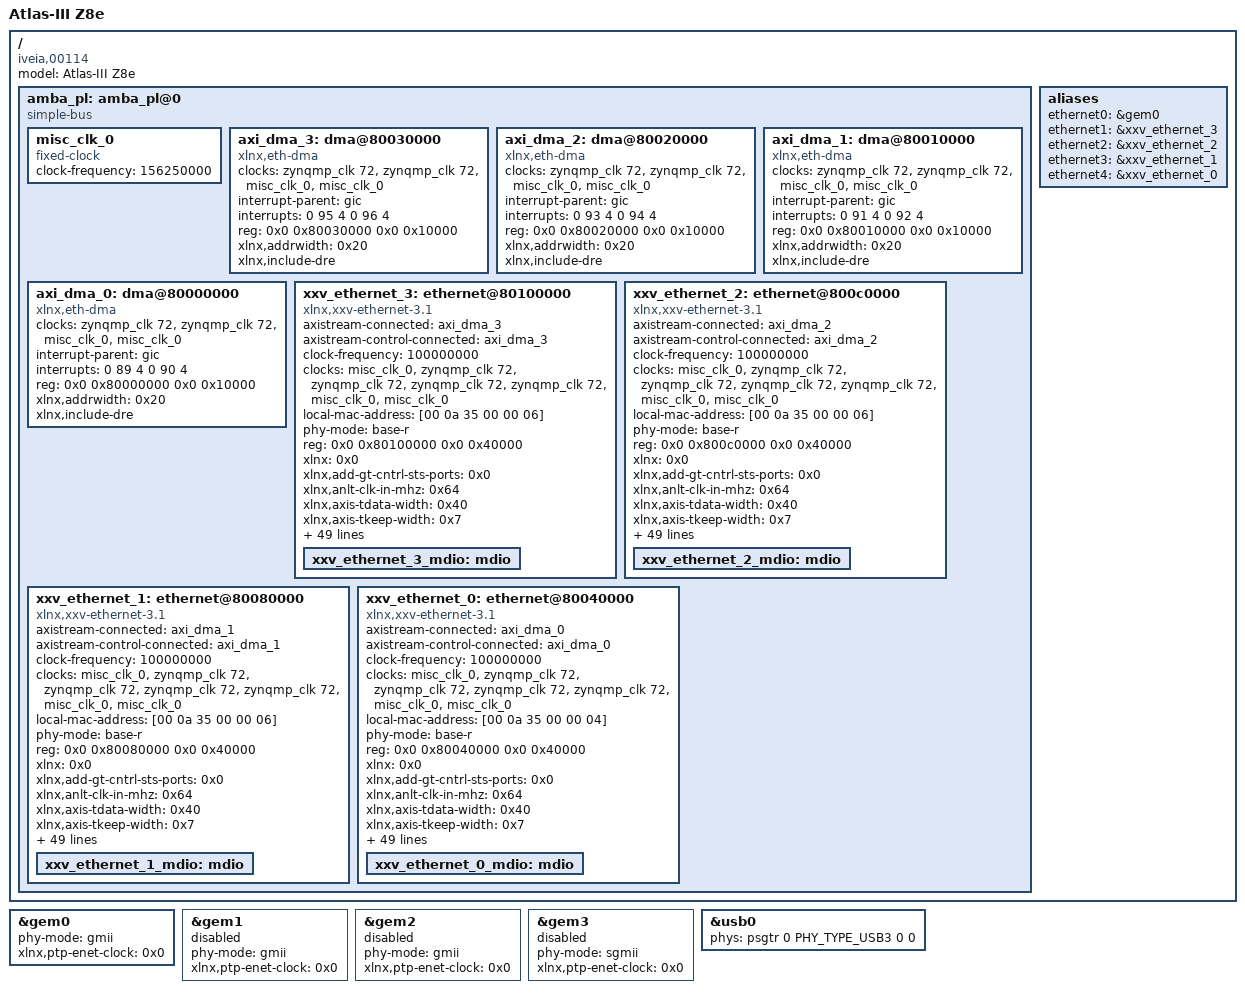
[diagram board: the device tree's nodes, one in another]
#include <atlas-z8-inc.dtsi>

/ {
  amba_pl: amba_pl@0 {
    #address-cells = <2>;
    #size-cells = <2>;
    compatible = "simple-bus";
    ranges ;
    misc_clk_0: misc_clk_0 {
      #clock-cells = <0>;
      clock-frequency = <156250000>;
      compatible = "fixed-clock";
    };
    axi_dma_3: dma@80030000 {
      #dma-cells = <1>;
      clock-names = "s_axi_lite_aclk", "m_axi_sg_aclk", "m_axi_mm2s_aclk", "m_axi_s2mm_aclk";
      clocks = <&zynqmp_clk 72>, <&zynqmp_clk 72>, <&misc_clk_0>, <&misc_clk_0>;
      compatible = "xlnx,eth-dma";
      interrupt-names = "mm2s_introut", "s2mm_introut";
      interrupt-parent = <&gic>;
      interrupts = <0 95 4 0 96 4>;
      reg = <0x0 0x80030000 0x0 0x10000>;
      xlnx,addrwidth = /bits/ 8 <0x20>;
      xlnx,include-dre ;
    };
    axi_dma_2: dma@80020000 {
      #dma-cells = <1>;
      clock-names = "s_axi_lite_aclk", "m_axi_sg_aclk", "m_axi_mm2s_aclk", "m_axi_s2mm_aclk";
      clocks = <&zynqmp_clk 72>, <&zynqmp_clk 72>, <&misc_clk_0>, <&misc_clk_0>;
      compatible = "xlnx,eth-dma";
      interrupt-names = "mm2s_introut", "s2mm_introut";
      interrupt-parent = <&gic>;
      interrupts = <0 93 4 0 94 4>;
      reg = <0x0 0x80020000 0x0 0x10000>;
      xlnx,addrwidth = /bits/ 8 <0x20>;
      xlnx,include-dre ;
    };
    axi_dma_1: dma@80010000 {
      #dma-cells = <1>;
      clock-names = "s_axi_lite_aclk", "m_axi_sg_aclk", "m_axi_mm2s_aclk", "m_axi_s2mm_aclk";
      clocks = <&zynqmp_clk 72>, <&zynqmp_clk 72>, <&misc_clk_0>, <&misc_clk_0>;
      compatible = "xlnx,eth-dma";
      interrupt-names = "mm2s_introut", "s2mm_introut";
      interrupt-parent = <&gic>;
      interrupts = <0 91 4 0 92 4>;
      reg = <0x0 0x80010000 0x0 0x10000>;
      xlnx,addrwidth = /bits/ 8 <0x20>;
      xlnx,include-dre ;
    };
    axi_dma_0: dma@80000000 {
      #dma-cells = <1>;
      clock-names = "s_axi_lite_aclk", "m_axi_sg_aclk", "m_axi_mm2s_aclk", "m_axi_s2mm_aclk";
      clocks = <&zynqmp_clk 72>, <&zynqmp_clk 72>, <&misc_clk_0>, <&misc_clk_0>;
      compatible = "xlnx,eth-dma";
      interrupt-names = "mm2s_introut", "s2mm_introut";
      interrupt-parent = <&gic>;
      interrupts = <0 89 4 0 90 4>;
      reg = <0x0 0x80000000 0x0 0x10000>;
      xlnx,addrwidth = /bits/ 8 <0x20>;
      xlnx,include-dre ;
    };
    // Lanes are backwards compared to the SFPs, so reverse the order here
    //  to get the devices enumerated in the proper order
    xxv_ethernet_3: ethernet@80100000 {
      axistream-connected = <&axi_dma_3>;
      axistream-control-connected = <&axi_dma_3>;
      clock-frequency = <100000000>;
      clock-names = "rx_core_clk_0", "dclk", "s_axi_aclk_0";
      clocks = <&misc_clk_0>, <&zynqmp_clk 72>, <&zynqmp_clk 72>;
      compatible = "xlnx,xxv-ethernet-3.1", "xlnx,xxv-ethernet-1.0";
      device_type = "network";
      local-mac-address = [00 0a 35 00 00 06];
      phy-mode = "base-r";
      reg = <0x0 0x80100000 0x0 0x40000>;
      xlnx = <0x0>;
      xlnx,add-gt-cntrl-sts-ports = <0x0>;
      xlnx,anlt-clk-in-mhz = <0x64>;
      xlnx,axis-tdata-width = <0x40>;
      xlnx,axis-tkeep-width = <0x7>;
      xlnx,base-r-kr = "BASE-R";
      xlnx,clocking = "Asynchronous";
      xlnx,core = "Ethernet MAC+PCS/PMA 64-bit";
      xlnx,data-path-interface = "AXI Stream";
      xlnx,enable-datapath-parity = <0x0>;
      xlnx,enable-pipeline-reg = <0x0>;
      xlnx,enable-preemption = <0x0>;
      xlnx,enable-preemption-fifo = <0x0>;
      xlnx,enable-rx-flow-control-logic = <0x0>;
      xlnx,enable-time-stamping = <0x0>;
      xlnx,enable-tx-flow-control-logic = <0x0>;
      xlnx,enable-vlane-adjust-mode = <0x0>;
      xlnx,family-chk = "zynquplus";
      xlnx,fast-sim-mode = <0x0>;
      xlnx,gt-diffctrl-width = <0x4>;
      xlnx,gt-drp-clk = "100.00";
      xlnx,gt-group-select = "Quad X0Y0";
      xlnx,gt-location = <0x1>;
      xlnx,gt-ref-clk-freq = "156.25";
      xlnx,gt-type = "GTH";
      xlnx,gtm-group-select = "NA";
      xlnx,include-auto-neg-lt-logic = "None";
      xlnx,include-axi4-interface = <0x1>;
      xlnx,include-dre ;
      xlnx,include-fec-logic = <0x0>;
      xlnx,include-hybrid-cmac-rsfec-logic = <0x0>;
      xlnx,include-rsfec-logic = <0x0>;
      xlnx,include-shared-logic = <0x1>;
      xlnx,include-statistics-counters = <0x1>;
      xlnx,include-user-fifo = <0x1>;
      xlnx,ins-loss-nyq = <0x1e>;
      xlnx,lane1-gt-loc = "X0Y7";
      xlnx,lane2-gt-loc = "NA";
      xlnx,lane3-gt-loc = "NA";
      xlnx,lane4-gt-loc = "NA";
      xlnx,line-rate = <0xa>;
      xlnx,mii-ctrl-width = <0x4>;
      xlnx,mii-data-width = <0x20>;
      xlnx,num-of-cores = <0x1>;
      xlnx,ptp-clocking-mode = <0x0>;
      xlnx,ptp-operation-mode = <0x2>;
      xlnx,runtime-switch = <0x0>;
      xlnx,rx-eq-mode = "AUTO";
      xlnx,rxmem = <0x40000>;
      xlnx,statistics-regs-type = <0x0>;
      xlnx,switch-1-10-25g = <0x0>;
      xlnx,tx-latency-adjust = <0x0>;
      xlnx,tx-total-bytes-width = <0x4>;
      xlnx,xgmii-interface = <0x1>;
      xxv_ethernet_3_mdio: mdio {
        #address-cells = <1>;
        #size-cells = <0>;
      };
    };
    xxv_ethernet_2: ethernet@800c0000 {
      axistream-connected = <&axi_dma_2>;
      axistream-control-connected = <&axi_dma_2>;
      clock-frequency = <100000000>;
      clock-names = "rx_core_clk_0", "dclk", "s_axi_aclk_0";
      clocks = <&misc_clk_0>, <&zynqmp_clk 72>, <&zynqmp_clk 72>;
      compatible = "xlnx,xxv-ethernet-3.1", "xlnx,xxv-ethernet-1.0";
      device_type = "network";
      local-mac-address = [00 0a 35 00 00 06];
      phy-mode = "base-r";
      reg = <0x0 0x800c0000 0x0 0x40000>;
      xlnx = <0x0>;
      xlnx,add-gt-cntrl-sts-ports = <0x0>;
      xlnx,anlt-clk-in-mhz = <0x64>;
      xlnx,axis-tdata-width = <0x40>;
      xlnx,axis-tkeep-width = <0x7>;
      xlnx,base-r-kr = "BASE-R";
      xlnx,clocking = "Asynchronous";
      xlnx,core = "Ethernet MAC+PCS/PMA 64-bit";
      xlnx,data-path-interface = "AXI Stream";
      xlnx,enable-datapath-parity = <0x0>;
      xlnx,enable-pipeline-reg = <0x0>;
      xlnx,enable-preemption = <0x0>;
      xlnx,enable-preemption-fifo = <0x0>;
      xlnx,enable-rx-flow-control-logic = <0x0>;
      xlnx,enable-time-stamping = <0x0>;
      xlnx,enable-tx-flow-control-logic = <0x0>;
      xlnx,enable-vlane-adjust-mode = <0x0>;
      xlnx,family-chk = "zynquplus";
      xlnx,fast-sim-mode = <0x0>;
      xlnx,gt-diffctrl-width = <0x4>;
      xlnx,gt-drp-clk = "100.00";
      xlnx,gt-group-select = "Quad X0Y0";
      xlnx,gt-location = <0x1>;
      xlnx,gt-ref-clk-freq = "156.25";
      xlnx,gt-type = "GTH";
      xlnx,gtm-group-select = "NA";
      xlnx,include-auto-neg-lt-logic = "None";
      xlnx,include-axi4-interface = <0x1>;
      xlnx,include-dre ;
      xlnx,include-fec-logic = <0x0>;
      xlnx,include-hybrid-cmac-rsfec-logic = <0x0>;
      xlnx,include-rsfec-logic = <0x0>;
      xlnx,include-shared-logic = <0x1>;
      xlnx,include-statistics-counters = <0x1>;
      xlnx,include-user-fifo = <0x1>;
      xlnx,ins-loss-nyq = <0x1e>;
      xlnx,lane1-gt-loc = "X0Y7";
      xlnx,lane2-gt-loc = "NA";
      xlnx,lane3-gt-loc = "NA";
      xlnx,lane4-gt-loc = "NA";
      xlnx,line-rate = <0xa>;
      xlnx,mii-ctrl-width = <0x4>;
      xlnx,mii-data-width = <0x20>;
      xlnx,num-of-cores = <0x1>;
      xlnx,ptp-clocking-mode = <0x0>;
      xlnx,ptp-operation-mode = <0x2>;
      xlnx,runtime-switch = <0x0>;
      xlnx,rx-eq-mode = "AUTO";
      xlnx,rxmem = <0x40000>;
      xlnx,statistics-regs-type = <0x0>;
      xlnx,switch-1-10-25g = <0x0>;
      xlnx,tx-latency-adjust = <0x0>;
      xlnx,tx-total-bytes-width = <0x4>;
      xlnx,xgmii-interface = <0x1>;
      xxv_ethernet_2_mdio: mdio {
        #address-cells = <1>;
        #size-cells = <0>;
      };
    };
    xxv_ethernet_1: ethernet@80080000 {
      axistream-connected = <&axi_dma_1>;
      axistream-control-connected = <&axi_dma_1>;
      clock-frequency = <100000000>;
      clock-names = "rx_core_clk_0", "dclk", "s_axi_aclk_0";
      clocks = <&misc_clk_0>, <&zynqmp_clk 72>, <&zynqmp_clk 72>;
      compatible = "xlnx,xxv-ethernet-3.1", "xlnx,xxv-ethernet-1.0";
      device_type = "network";
      local-mac-address = [00 0a 35 00 00 06];
      phy-mode = "base-r";
      reg = <0x0 0x80080000 0x0 0x40000>;
      xlnx = <0x0>;
      xlnx,add-gt-cntrl-sts-ports = <0x0>;
      xlnx,anlt-clk-in-mhz = <0x64>;
      xlnx,axis-tdata-width = <0x40>;
      xlnx,axis-tkeep-width = <0x7>;
      xlnx,base-r-kr = "BASE-R";
      xlnx,clocking = "Asynchronous";
      xlnx,core = "Ethernet MAC+PCS/PMA 64-bit";
      xlnx,data-path-interface = "AXI Stream";
      xlnx,enable-datapath-parity = <0x0>;
      xlnx,enable-pipeline-reg = <0x0>;
      xlnx,enable-preemption = <0x0>;
      xlnx,enable-preemption-fifo = <0x0>;
      xlnx,enable-rx-flow-control-logic = <0x0>;
      xlnx,enable-time-stamping = <0x0>;
      xlnx,enable-tx-flow-control-logic = <0x0>;
      xlnx,enable-vlane-adjust-mode = <0x0>;
      xlnx,family-chk = "zynquplus";
      xlnx,fast-sim-mode = <0x0>;
      xlnx,gt-diffctrl-width = <0x4>;
      xlnx,gt-drp-clk = "100.00";
      xlnx,gt-group-select = "Quad X0Y0";
      xlnx,gt-location = <0x1>;
      xlnx,gt-ref-clk-freq = "156.25";
      xlnx,gt-type = "GTH";
      xlnx,gtm-group-select = "NA";
      xlnx,include-auto-neg-lt-logic = "None";
      xlnx,include-axi4-interface = <0x1>;
      xlnx,include-dre ;
      xlnx,include-fec-logic = <0x0>;
      xlnx,include-hybrid-cmac-rsfec-logic = <0x0>;
      xlnx,include-rsfec-logic = <0x0>;
      xlnx,include-shared-logic = <0x1>;
      xlnx,include-statistics-counters = <0x1>;
      xlnx,include-user-fifo = <0x1>;
      xlnx,ins-loss-nyq = <0x1e>;
      xlnx,lane1-gt-loc = "X0Y7";
      xlnx,lane2-gt-loc = "NA";
      xlnx,lane3-gt-loc = "NA";
      xlnx,lane4-gt-loc = "NA";
      xlnx,line-rate = <0xa>;
      xlnx,mii-ctrl-width = <0x4>;
      xlnx,mii-data-width = <0x20>;
      xlnx,num-of-cores = <0x1>;
      xlnx,ptp-clocking-mode = <0x0>;
      xlnx,ptp-operation-mode = <0x2>;
      xlnx,runtime-switch = <0x0>;
      xlnx,rx-eq-mode = "AUTO";
      xlnx,rxmem = <0x40000>;
      xlnx,statistics-regs-type = <0x0>;
      xlnx,switch-1-10-25g = <0x0>;
      xlnx,tx-latency-adjust = <0x0>;
      xlnx,tx-total-bytes-width = <0x4>;
      xlnx,xgmii-interface = <0x1>;
      xxv_ethernet_1_mdio: mdio {
        #address-cells = <1>;
        #size-cells = <0>;
      };
    };
    xxv_ethernet_0: ethernet@80040000 {
      axistream-connected = <&axi_dma_0>;
      axistream-control-connected = <&axi_dma_0>;
      clock-frequency = <100000000>;
      clock-names = "rx_core_clk_0", "dclk", "s_axi_aclk_0";
      clocks = <&misc_clk_0>, <&zynqmp_clk 72>, <&zynqmp_clk 72>;
      compatible = "xlnx,xxv-ethernet-3.1", "xlnx,xxv-ethernet-1.0";
      device_type = "network";
      local-mac-address = [00 0a 35 00 00 04];
      phy-mode = "base-r";
      reg = <0x0 0x80040000 0x0 0x40000>;
      xlnx = <0x0>;
      xlnx,add-gt-cntrl-sts-ports = <0x0>;
      xlnx,anlt-clk-in-mhz = <0x64>;
      xlnx,axis-tdata-width = <0x40>;
      xlnx,axis-tkeep-width = <0x7>;
      xlnx,base-r-kr = "BASE-R";
      xlnx,clocking = "Asynchronous";
      xlnx,core = "Ethernet MAC+PCS/PMA 64-bit";
      xlnx,data-path-interface = "AXI Stream";
      xlnx,enable-datapath-parity = <0x0>;
      xlnx,enable-pipeline-reg = <0x0>;
      xlnx,enable-preemption = <0x0>;
      xlnx,enable-preemption-fifo = <0x0>;
      xlnx,enable-rx-flow-control-logic = <0x0>;
      xlnx,enable-time-stamping = <0x0>;
      xlnx,enable-tx-flow-control-logic = <0x0>;
      xlnx,enable-vlane-adjust-mode = <0x0>;
      xlnx,family-chk = "zynquplus";
      xlnx,fast-sim-mode = <0x0>;
      xlnx,gt-diffctrl-width = <0x4>;
      xlnx,gt-drp-clk = "100.00";
      xlnx,gt-group-select = "Quad X0Y0";
      xlnx,gt-location = <0x1>;
      xlnx,gt-ref-clk-freq = "156.25";
      xlnx,gt-type = "GTH";
      xlnx,gtm-group-select = "NA";
      xlnx,include-auto-neg-lt-logic = "None";
      xlnx,include-axi4-interface = <0x1>;
      xlnx,include-dre ;
      xlnx,include-fec-logic = <0x0>;
      xlnx,include-hybrid-cmac-rsfec-logic = <0x0>;
      xlnx,include-rsfec-logic = <0x0>;
      xlnx,include-shared-logic = <0x1>;
      xlnx,include-statistics-counters = <0x1>;
      xlnx,include-user-fifo = <0x1>;
      xlnx,ins-loss-nyq = <0x1e>;
      xlnx,lane1-gt-loc = "X0Y7";
      xlnx,lane2-gt-loc = "NA";
      xlnx,lane3-gt-loc = "NA";
      xlnx,lane4-gt-loc = "NA";
      xlnx,line-rate = <0xa>;
      xlnx,mii-ctrl-width = <0x4>;
      xlnx,mii-data-width = <0x20>;
      xlnx,num-of-cores = <0x1>;
      xlnx,ptp-clocking-mode = <0x0>;
      xlnx,ptp-operation-mode = <0x2>;
      xlnx,runtime-switch = <0x0>;
      xlnx,rx-eq-mode = "AUTO";
      xlnx,rxmem = <0x40000>;
      xlnx,statistics-regs-type = <0x0>;
      xlnx,switch-1-10-25g = <0x0>;
      xlnx,tx-latency-adjust = <0x0>;
      xlnx,tx-total-bytes-width = <0x4>;
      xlnx,xgmii-interface = <0x1>;
      xxv_ethernet_0_mdio: mdio {
        #address-cells = <1>;
        #size-cells = <0>;
      };
    };
  };
};

&gem0 {
  phy-mode = "gmii";
  status = "okay";
  xlnx,ptp-enet-clock = <0x0>;
};
&gem1 {
  phy-mode = "gmii";
  status = "disabled";
  xlnx,ptp-enet-clock = <0x0>;
};
&gem2 {
  phy-mode = "gmii";
  status = "disabled";
  xlnx,ptp-enet-clock = <0x0>;
};
&gem3 {
  phy-mode = "sgmii";
  status = "disabled";
  xlnx,ptp-enet-clock = <0x0>;
};
&xxv_ethernet_0 {
  clock-names = "rx_core_clk", "dclk", "s_axi_aclk", "s_axi_lite_aclk", "m_axi_sg_aclk", "m_axi_mm2s_aclk", "m_axi_s2mm_aclk";
  clocks = <&misc_clk_0>,  <&zynqmp_clk 72>,  <&zynqmp_clk 72>, <&zynqmp_clk 72>, <&zynqmp_clk 72>, <&misc_clk_0>, <&misc_clk_0>;
};
&xxv_ethernet_1 {
  clock-names = "rx_core_clk", "dclk", "s_axi_aclk", "s_axi_lite_aclk", "m_axi_sg_aclk", "m_axi_mm2s_aclk", "m_axi_s2mm_aclk";
  clocks = <&misc_clk_0>,  <&zynqmp_clk 72>,  <&zynqmp_clk 72>, <&zynqmp_clk 72>, <&zynqmp_clk 72>, <&misc_clk_0>, <&misc_clk_0>;
};
&xxv_ethernet_2 {
  clock-names = "rx_core_clk", "dclk", "s_axi_aclk", "s_axi_lite_aclk", "m_axi_sg_aclk", "m_axi_mm2s_aclk", "m_axi_s2mm_aclk";
  clocks = <&misc_clk_0>,  <&zynqmp_clk 72>,  <&zynqmp_clk 72>, <&zynqmp_clk 72>, <&zynqmp_clk 72>, <&misc_clk_0>, <&misc_clk_0>;
};
&xxv_ethernet_3 {
  clock-names = "rx_core_clk", "dclk", "s_axi_aclk", "s_axi_lite_aclk", "m_axi_sg_aclk", "m_axi_mm2s_aclk", "m_axi_s2mm_aclk";
  clocks = <&misc_clk_0>,  <&zynqmp_clk 72>,  <&zynqmp_clk 72>, <&zynqmp_clk 72>, <&zynqmp_clk 72>, <&misc_clk_0>, <&misc_clk_0>;
};

/ {
  model = "Atlas-III Z8e";
  compatible = "iveia,00114", "iveia,atlas-z8", "xlnx,zynqmp";
};

/ {
  aliases {
    ethernet0 = &gem0;
    ethernet1 = &xxv_ethernet_3;
    ethernet2 = &xxv_ethernet_2;
    ethernet3 = &xxv_ethernet_1;
    ethernet4 = &xxv_ethernet_0;
  };
};

&usb0 {
  // PSGTR Lane 0, USB0, PSGTR refclk0 (100MHz)
  phys = <&psgtr 0 PHY_TYPE_USB3 0 0>;
};

